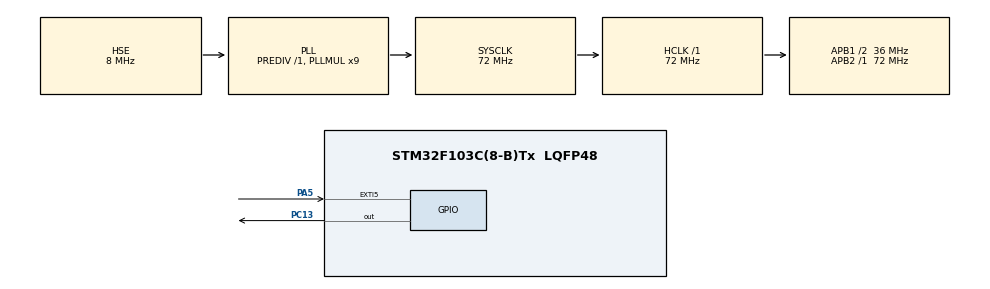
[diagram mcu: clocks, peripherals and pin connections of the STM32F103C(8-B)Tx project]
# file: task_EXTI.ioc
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Mcu.Family=STM32F1
Mcu.Name=STM32F103C(8-B)Tx
Mcu.Package=LQFP48
NVIC.EXTI9_5_IRQn=true\:0\:0\:false\:false\:true\:true\:true\:true
NVIC.PriorityGroup=NVIC_PRIORITYGROUP_4
PA13.Mode=Serial_Wire
PA13.Signal=SYS_JTMS-SWDIO
PA14.Mode=Serial_Wire
PA14.Signal=SYS_JTCK-SWCLK
PA5.GPIO_ModeDefaultEXTI=GPIO_MODE_IT_FALLING
PA5.GPIO_PuPd=GPIO_PULLUP
PA5.Signal=GPXTI5
PC13-TAMPER-RTC.GPIO_ModeDefaultOutputPP=GPIO_MODE_OUTPUT_PP
PC13-TAMPER-RTC.GPIO_PuPd=GPIO_NOPULL
PC13-TAMPER-RTC.PinState=GPIO_PIN_SET
PC13-TAMPER-RTC.Signal=GPIO_Output
PD0-OSC_IN.Mode=HSE-External-Oscillator
PD0-OSC_IN.Signal=RCC_OSC_IN
PD1-OSC_OUT.Mode=HSE-External-Oscillator
PD1-OSC_OUT.Signal=RCC_OSC_OUT
ProjectManager.HeapSize=0x200
ProjectManager.StackSize=0x400
ProjectManager.TargetToolchain=STM32CubeIDE
RCC.AHBFreq_Value=72000000
RCC.APB1CLKDivider=RCC_HCLK_DIV2
RCC.APB1Freq_Value=36000000
RCC.APB1TimFreq_Value=72000000
RCC.APB2Freq_Value=72000000
RCC.APB2TimFreq_Value=72000000
RCC.HCLKFreq_Value=72000000
RCC.PLLMUL=RCC_PLL_MUL9
RCC.PLLSourceVirtual=RCC_PLLSOURCE_HSE
RCC.SYSCLKFreq_VALUE=72000000
RCC.SYSCLKSource=RCC_SYSCLKSOURCE_PLLCLK
RCC.USBFreq_Value=72000000
board=custom

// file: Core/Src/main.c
/* USER CODE BEGIN Header */
/**
  ******************************************************************************
  * @file           : main.c
  * @brief          : Main program body
  ******************************************************************************
  * @attention
  *
  * Copyright (c) 2025 STMicroelectronics.
  * All rights reserved.
  *
  * This software is licensed under terms that can be found in the LICENSE file
  * in the root directory of this software component.
  * If no LICENSE file comes with this software, it is provided AS-IS.
  *
  ******************************************************************************
  */
/* USER CODE END Header */
#include "main.h"

/* USER CODE BEGIN PD */
#define LED_PIN    GPIO_PIN_13  // LED引脚（PC13）
#define LED_PORT   GPIOC        // LED端口
#define KEY_PIN    GPIO_PIN_5   // 按键引脚（PA5）
#define KEY_PORT   GPIOA        // 按键端口
#define LED_ON_TIME 1000         // LED点亮时长（ms）
/* USER CODE END PD */

GPIO_InitTypeDef GPIO_InitStruct = {0};

/* USER CODE BEGIN PV */
uint8_t key_exti_flag = 0;  // 中断标志位
/* USER CODE END PV */

void SystemClock_Config(void);
static void MX_GPIO_Init(void);
/* USER CODE BEGIN PFP */
void LED_ON(void);   // LED点亮（低电平）
void LED_OFF(void);  // LED熄灭（高电平）
/* USER CODE END PFP */

/* USER CODE BEGIN 0 */

void LED_ON(void)
{
  HAL_GPIO_WritePin(LED_PORT, LED_PIN, GPIO_PIN_RESET);
}

void LED_OFF(void)
{
  HAL_GPIO_WritePin(LED_PORT, LED_PIN, GPIO_PIN_SET);
}

// EXTI中断回调函数
void HAL_GPIO_EXTI_Callback(uint16_t GPIO_Pin)
{
  if (GPIO_Pin == KEY_PIN)  // 仅判断PA5触发
  {
    key_exti_flag = 1;  // 置位标志位
  }
}

/* USER CODE END 0 */

int main(void)
{

  /* MCU Configuration--------------------------------------------------------*/
  HAL_Init();
  SystemClock_Config();
  MX_GPIO_Init();

  /* USER CODE BEGIN 2 */
  LED_OFF();  // 初始化熄灭
  /* USER CODE END 2 */

  /* Infinite loop */
  /* USER CODE BEGIN WHILE */
  while (1)
  {
    if (key_exti_flag == 1)
    {
      LED_ON();
      HAL_Delay(LED_ON_TIME); // 匹配宏定义1000ms
      LED_OFF();
      key_exti_flag = 0;      // 清除标志位
    }
    /* USER CODE END WHILE */

  }
}

void SystemClock_Config(void)
{
  RCC_OscInitTypeDef RCC_OscInitStruct = {0};
  RCC_ClkInitTypeDef RCC_ClkInitStruct = {0};

  // 配置HSE外部晶振（8MHz→72MHz）
  RCC_OscInitStruct.OscillatorType = RCC_OSCILLATORTYPE_HSE;
  RCC_OscInitStruct.HSEState = RCC_HSE_ON;
  RCC_OscInitStruct.HSEPredivValue = RCC_HSE_PREDIV_DIV1;
  RCC_OscInitStruct.PLL.PLLState = RCC_PLL_ON;
  RCC_OscInitStruct.PLL.PLLSource = RCC_PLLSOURCE_HSE;
  RCC_OscInitStruct.PLL.PLLMUL = RCC_PLL_MUL9;
  if (HAL_RCC_OscConfig(&RCC_OscInitStruct) != HAL_OK)
  {
    Error_Handler();
  }

  // 配置系统时钟
  RCC_ClkInitStruct.ClockType = RCC_CLOCKTYPE_HCLK|RCC_CLOCKTYPE_SYSCLK
                              |RCC_CLOCKTYPE_PCLK1|RCC_CLOCKTYPE_PCLK2;
  RCC_ClkInitStruct.SYSCLKSource = RCC_SYSCLKSOURCE_PLLCLK;
  RCC_ClkInitStruct.AHBCLKDivider = RCC_SYSCLK_DIV1;
  RCC_ClkInitStruct.APB1CLKDivider = RCC_HCLK_DIV2;
  RCC_ClkInitStruct.APB2CLKDivider = RCC_HCLK_DIV1;

  if (HAL_RCC_ClockConfig(&RCC_ClkInitStruct, FLASH_LATENCY_2) != HAL_OK)
  {
    Error_Handler();
  }
}

static void MX_GPIO_Init(void)
{
  // 使能GPIOA和GPIOC时钟
  __HAL_RCC_GPIOA_CLK_ENABLE();
  __HAL_RCC_GPIOC_CLK_ENABLE();

  // PA5配置：EXTI下降沿中断+内部上拉
  GPIO_InitStruct.Pin = KEY_PIN;
  GPIO_InitStruct.Mode = GPIO_MODE_IT_FALLING;
  GPIO_InitStruct.Pull = GPIO_PULLUP;
  GPIO_InitStruct.Speed = GPIO_SPEED_FREQ_LOW;
  HAL_GPIO_Init(KEY_PORT, &GPIO_InitStruct);

  // PC13配置：输出+初始高电平+低速
  GPIO_InitStruct.Pin = LED_PIN;
  GPIO_InitStruct.Mode = GPIO_MODE_OUTPUT_PP;
  GPIO_InitStruct.Pull = GPIO_NOPULL;
  GPIO_InitStruct.Speed = GPIO_SPEED_FREQ_LOW;
  HAL_GPIO_Init(LED_PORT, &GPIO_InitStruct);

  // NVIC配置
  HAL_NVIC_SetPriority(EXTI9_5_IRQn, 0, 0);
  HAL_NVIC_EnableIRQ(EXTI9_5_IRQn);
}

void Error_Handler(void)
{
  /* USER CODE BEGIN Error_Handler_Debug */
  __disable_irq();
  while (1)
  {
    // 错误时LED快速闪烁
    LED_ON();
    HAL_Delay(100);
    LED_OFF();
    HAL_Delay(100);
  }
  /* USER CODE END Error_Handler_Debug */
}
